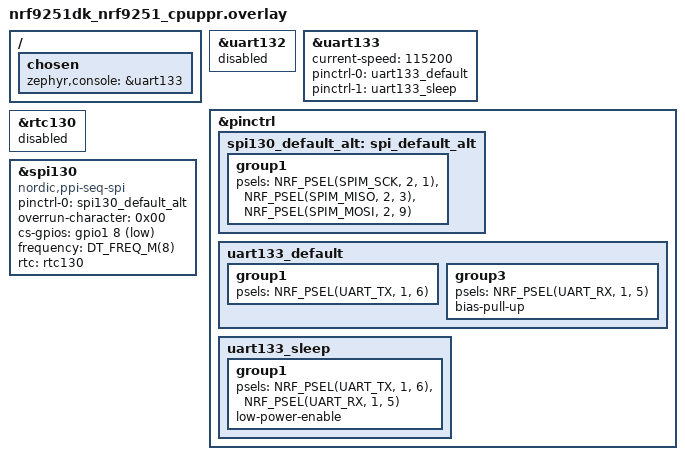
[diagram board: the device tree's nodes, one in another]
/*
 * Copyright (c) 2026 Nordic Semiconductor ASA
 *
 * SPDX-License-Identifier: LicenseRef-Nordic-5-Clause
 */

/ {
	chosen {
		zephyr,console = &uart133;
	};
};

&uart132 {
	status = "disabled";
};

&uart133 {
	status = "okay";
	current-speed = <115200>;
	pinctrl-0 = <&uart133_default>;
	pinctrl-1 = <&uart133_sleep>;
	pinctrl-names = "default", "sleep";
};

&pinctrl {
	spi130_default_alt: spi_default_alt {
		group1 {
			psels = <NRF_PSEL(SPIM_SCK, 2, 1)>,
				<NRF_PSEL(SPIM_MISO, 2, 3)>,
				<NRF_PSEL(SPIM_MOSI, 2, 9)>;
		};
	};

	uart133_default: uart133_default {
		group1 {
			psels = <NRF_PSEL(UART_TX, 1, 6)>;
		};

		group3 {
			psels = <NRF_PSEL(UART_RX, 1, 5)>;
			bias-pull-up;
		};
	};

	uart133_sleep: uart133_sleep {
		group1 {
			psels = <NRF_PSEL(UART_TX, 1, 6)>,
				<NRF_PSEL(UART_RX, 1, 5)>;
			low-power-enable;
		};
	};
};

&rtc130 {
	status = "reserved";
};

sample_spi: &spi130 {
	compatible = "nordic,ppi-seq-spi";
	status = "okay";
	pinctrl-0 = <&spi130_default_alt>;
	pinctrl-names = "default";
	overrun-character = <0x00>;
	cs-gpios = <&gpio1 8 GPIO_ACTIVE_LOW>;
	frequency = <DT_FREQ_M(8)>;
	rtc = <&rtc130>;
};
